# Espressif register map
File version: 1.0
CPU: Xtensa LX6 1, little endian, no MPU, FPU, 3 interrupt priority bits
Registers are 32-bit, access not given, reset 0x0 unless marked. A register's access mark holds for its fields unless they carry their own. Offsets are from the block's base; [hi:lo] are bit positions; {n}, {i} and the like mark numbered series.

## RTCCNTL
Base 0x3FF48000
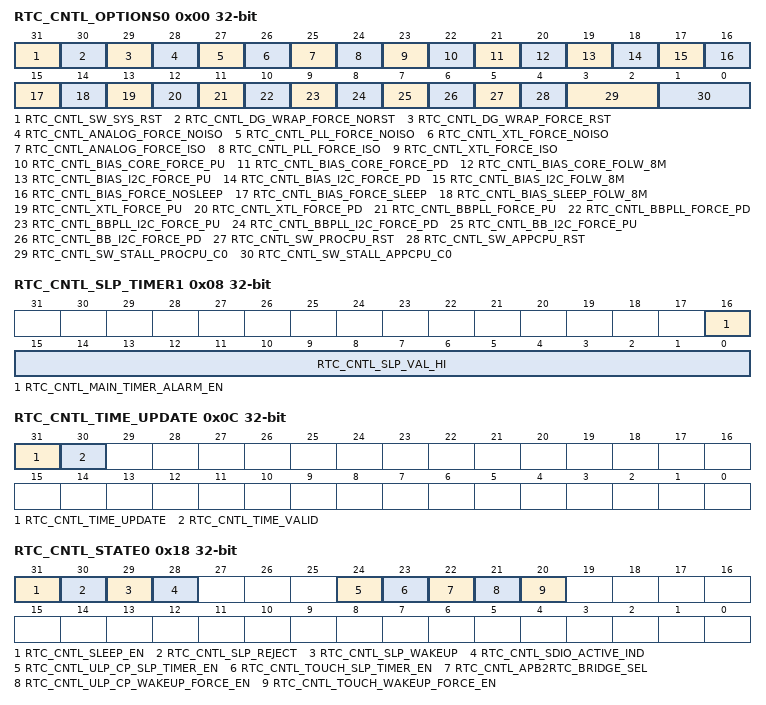
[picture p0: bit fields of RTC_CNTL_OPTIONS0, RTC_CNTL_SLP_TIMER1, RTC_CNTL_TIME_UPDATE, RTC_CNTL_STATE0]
0x00 RTC_CNTL_OPTIONS0
  [31] RTC_CNTL_SW_SYS_RST, [30] RTC_CNTL_DG_WRAP_FORCE_NORST, [29] RTC_CNTL_DG_WRAP_FORCE_RST, [28] RTC_CNTL_ANALOG_FORCE_NOISO, [27] RTC_CNTL_PLL_FORCE_NOISO, [26] RTC_CNTL_XTL_FORCE_NOISO, [25] RTC_CNTL_ANALOG_FORCE_ISO, [24] RTC_CNTL_PLL_FORCE_ISO, [23] RTC_CNTL_XTL_FORCE_ISO, [22] RTC_CNTL_BIAS_CORE_FORCE_PU, [21] RTC_CNTL_BIAS_CORE_FORCE_PD, [20] RTC_CNTL_BIAS_CORE_FOLW_8M, [19] RTC_CNTL_BIAS_I2C_FORCE_PU, [18] RTC_CNTL_BIAS_I2C_FORCE_PD, [17] RTC_CNTL_BIAS_I2C_FOLW_8M, [16] RTC_CNTL_BIAS_FORCE_NOSLEEP, [15] RTC_CNTL_BIAS_FORCE_SLEEP, [14] RTC_CNTL_BIAS_SLEEP_FOLW_8M, [13] RTC_CNTL_XTL_FORCE_PU, [12] RTC_CNTL_XTL_FORCE_PD, [11] RTC_CNTL_BBPLL_FORCE_PU, [10] RTC_CNTL_BBPLL_FORCE_PD, [9] RTC_CNTL_BBPLL_I2C_FORCE_PU, [8] RTC_CNTL_BBPLL_I2C_FORCE_PD, [7] RTC_CNTL_BB_I2C_FORCE_PU, [6] RTC_CNTL_BB_I2C_FORCE_PD, [5] RTC_CNTL_SW_PROCPU_RST, [4] RTC_CNTL_SW_APPCPU_RST, [3:2] RTC_CNTL_SW_STALL_PROCPU_C0, [1:0] RTC_CNTL_SW_STALL_APPCPU_C0
0x04 RTC_CNTL_SLP_TIMER0
  [31:0] RTC_CNTL_SLP_VAL_LO
0x08 RTC_CNTL_SLP_TIMER1
  [16] RTC_CNTL_MAIN_TIMER_ALARM_EN, [15:0] RTC_CNTL_SLP_VAL_HI
0x0C RTC_CNTL_TIME_UPDATE
  [31] RTC_CNTL_TIME_UPDATE, [30] RTC_CNTL_TIME_VALID
0x10 RTC_CNTL_TIME0
  [31:0] RTC_CNTL_TIME_LO
0x14 RTC_CNTL_TIME1
  [15:0] RTC_CNTL_TIME_HI
0x18 RTC_CNTL_STATE0
  [31] RTC_CNTL_SLEEP_EN, [30] RTC_CNTL_SLP_REJECT, [29] RTC_CNTL_SLP_WAKEUP, [28] RTC_CNTL_SDIO_ACTIVE_IND, [24] RTC_CNTL_ULP_CP_SLP_TIMER_EN, [23] RTC_CNTL_TOUCH_SLP_TIMER_EN, [22] RTC_CNTL_APB2RTC_BRIDGE_SEL, [21] RTC_CNTL_ULP_CP_WAKEUP_FORCE_EN, [20] RTC_CNTL_TOUCH_WAKEUP_FORCE_EN
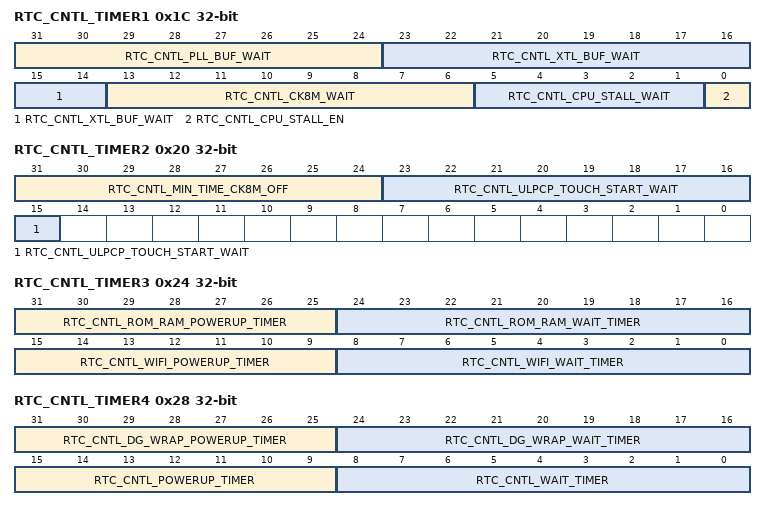
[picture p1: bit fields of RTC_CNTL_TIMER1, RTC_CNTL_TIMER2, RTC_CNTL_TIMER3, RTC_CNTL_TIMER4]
0x1C RTC_CNTL_TIMER1
  [31:24] RTC_CNTL_PLL_BUF_WAIT, [23:14] RTC_CNTL_XTL_BUF_WAIT, [13:6] RTC_CNTL_CK8M_WAIT, [5:1] RTC_CNTL_CPU_STALL_WAIT, [0] RTC_CNTL_CPU_STALL_EN
0x20 RTC_CNTL_TIMER2
  [31:24] RTC_CNTL_MIN_TIME_CK8M_OFF, [23:15] RTC_CNTL_ULPCP_TOUCH_START_WAIT
0x24 RTC_CNTL_TIMER3
  [31:25] RTC_CNTL_ROM_RAM_POWERUP_TIMER, [24:16] RTC_CNTL_ROM_RAM_WAIT_TIMER, [15:9] RTC_CNTL_WIFI_POWERUP_TIMER, [8:0] RTC_CNTL_WIFI_WAIT_TIMER
0x28 RTC_CNTL_TIMER4
  [31:25] RTC_CNTL_DG_WRAP_POWERUP_TIMER, [24:16] RTC_CNTL_DG_WRAP_WAIT_TIMER, [15:9] RTC_CNTL_POWERUP_TIMER, [8:0] RTC_CNTL_WAIT_TIMER
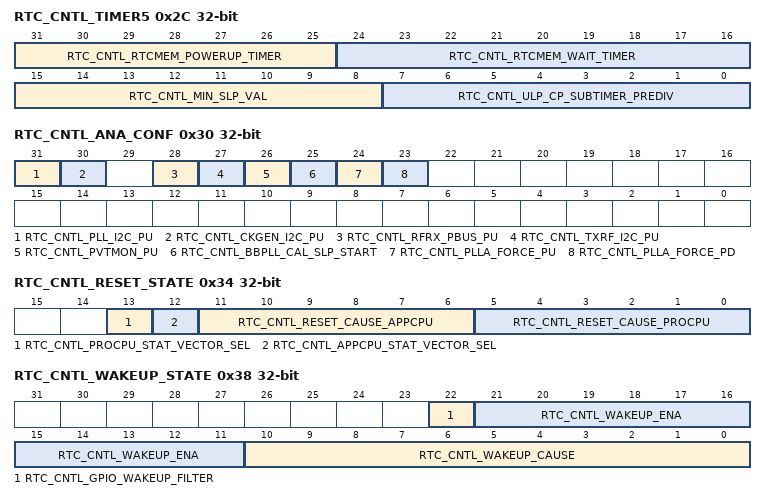
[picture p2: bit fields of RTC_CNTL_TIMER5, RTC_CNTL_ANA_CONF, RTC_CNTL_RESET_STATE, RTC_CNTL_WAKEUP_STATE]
0x2C RTC_CNTL_TIMER5
  [31:25] RTC_CNTL_RTCMEM_POWERUP_TIMER, [24:16] RTC_CNTL_RTCMEM_WAIT_TIMER, [15:8] RTC_CNTL_MIN_SLP_VAL, [7:0] RTC_CNTL_ULP_CP_SUBTIMER_PREDIV
0x30 RTC_CNTL_ANA_CONF
  [31] RTC_CNTL_PLL_I2C_PU, [30] RTC_CNTL_CKGEN_I2C_PU, [28] RTC_CNTL_RFRX_PBUS_PU, [27] RTC_CNTL_TXRF_I2C_PU, [26] RTC_CNTL_PVTMON_PU, [25] RTC_CNTL_BBPLL_CAL_SLP_START, [24] RTC_CNTL_PLLA_FORCE_PU, [23] RTC_CNTL_PLLA_FORCE_PD
0x34 RTC_CNTL_RESET_STATE
  [13] RTC_CNTL_PROCPU_STAT_VECTOR_SEL, [12] RTC_CNTL_APPCPU_STAT_VECTOR_SEL, [11:6] RTC_CNTL_RESET_CAUSE_APPCPU, [5:0] RTC_CNTL_RESET_CAUSE_PROCPU
0x38 RTC_CNTL_WAKEUP_STATE
  [22] RTC_CNTL_GPIO_WAKEUP_FILTER, [21:11] RTC_CNTL_WAKEUP_ENA, [10:0] RTC_CNTL_WAKEUP_CAUSE
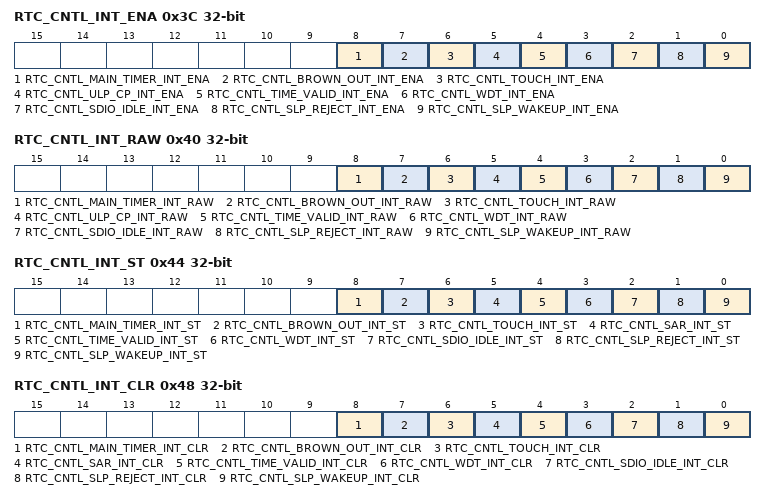
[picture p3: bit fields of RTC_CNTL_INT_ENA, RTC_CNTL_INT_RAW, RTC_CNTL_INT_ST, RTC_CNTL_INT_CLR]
0x3C RTC_CNTL_INT_ENA
  [8] RTC_CNTL_MAIN_TIMER_INT_ENA, [7] RTC_CNTL_BROWN_OUT_INT_ENA, [6] RTC_CNTL_TOUCH_INT_ENA, [5] RTC_CNTL_ULP_CP_INT_ENA, [4] RTC_CNTL_TIME_VALID_INT_ENA, [3] RTC_CNTL_WDT_INT_ENA, [2] RTC_CNTL_SDIO_IDLE_INT_ENA, [1] RTC_CNTL_SLP_REJECT_INT_ENA, [0] RTC_CNTL_SLP_WAKEUP_INT_ENA
0x40 RTC_CNTL_INT_RAW
  [8] RTC_CNTL_MAIN_TIMER_INT_RAW, [7] RTC_CNTL_BROWN_OUT_INT_RAW, [6] RTC_CNTL_TOUCH_INT_RAW, [5] RTC_CNTL_ULP_CP_INT_RAW, [4] RTC_CNTL_TIME_VALID_INT_RAW, [3] RTC_CNTL_WDT_INT_RAW, [2] RTC_CNTL_SDIO_IDLE_INT_RAW, [1] RTC_CNTL_SLP_REJECT_INT_RAW, [0] RTC_CNTL_SLP_WAKEUP_INT_RAW
0x44 RTC_CNTL_INT_ST
  [8] RTC_CNTL_MAIN_TIMER_INT_ST, [7] RTC_CNTL_BROWN_OUT_INT_ST, [6] RTC_CNTL_TOUCH_INT_ST, [5] RTC_CNTL_SAR_INT_ST, [4] RTC_CNTL_TIME_VALID_INT_ST, [3] RTC_CNTL_WDT_INT_ST, [2] RTC_CNTL_SDIO_IDLE_INT_ST, [1] RTC_CNTL_SLP_REJECT_INT_ST, [0] RTC_CNTL_SLP_WAKEUP_INT_ST
0x48 RTC_CNTL_INT_CLR
  [8] RTC_CNTL_MAIN_TIMER_INT_CLR, [7] RTC_CNTL_BROWN_OUT_INT_CLR, [6] RTC_CNTL_TOUCH_INT_CLR, [5] RTC_CNTL_SAR_INT_CLR, [4] RTC_CNTL_TIME_VALID_INT_CLR, [3] RTC_CNTL_WDT_INT_CLR, [2] RTC_CNTL_SDIO_IDLE_INT_CLR, [1] RTC_CNTL_SLP_REJECT_INT_CLR, [0] RTC_CNTL_SLP_WAKEUP_INT_CLR
{0x4C+4i} RTC_CNTL_STORE{i} (i=0..3)
  [31:0] RTC_CNTL_SCRATCH{i}
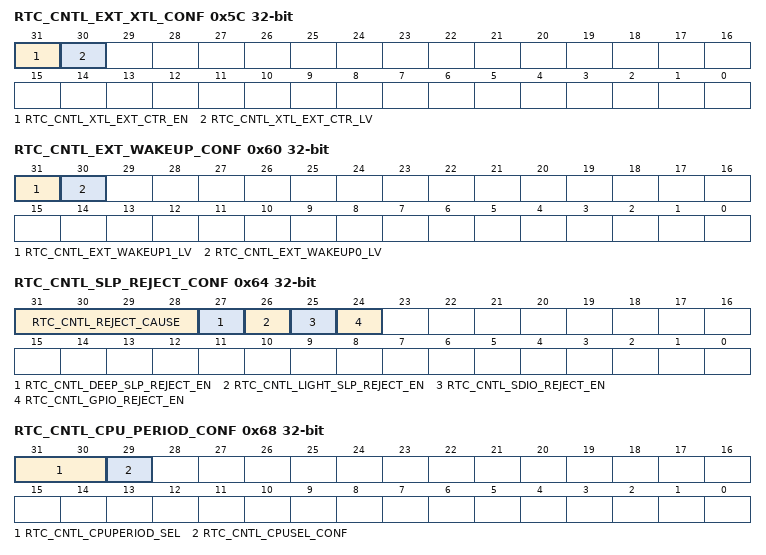
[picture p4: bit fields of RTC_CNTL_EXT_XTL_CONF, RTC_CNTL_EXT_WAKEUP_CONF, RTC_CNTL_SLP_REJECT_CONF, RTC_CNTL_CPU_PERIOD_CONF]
0x5C RTC_CNTL_EXT_XTL_CONF
  [31] RTC_CNTL_XTL_EXT_CTR_EN, [30] RTC_CNTL_XTL_EXT_CTR_LV
0x60 RTC_CNTL_EXT_WAKEUP_CONF
  [31] RTC_CNTL_EXT_WAKEUP1_LV, [30] RTC_CNTL_EXT_WAKEUP0_LV
0x64 RTC_CNTL_SLP_REJECT_CONF
  [31:28] RTC_CNTL_REJECT_CAUSE, [27] RTC_CNTL_DEEP_SLP_REJECT_EN, [26] RTC_CNTL_LIGHT_SLP_REJECT_EN, [25] RTC_CNTL_SDIO_REJECT_EN, [24] RTC_CNTL_GPIO_REJECT_EN
0x68 RTC_CNTL_CPU_PERIOD_CONF
  [31:30] RTC_CNTL_CPUPERIOD_SEL, [29] RTC_CNTL_CPUSEL_CONF
0x6C RTC_CNTL_SDIO_ACT_CONF
  [31:22] RTC_CNTL_SDIO_ACT_DNUM
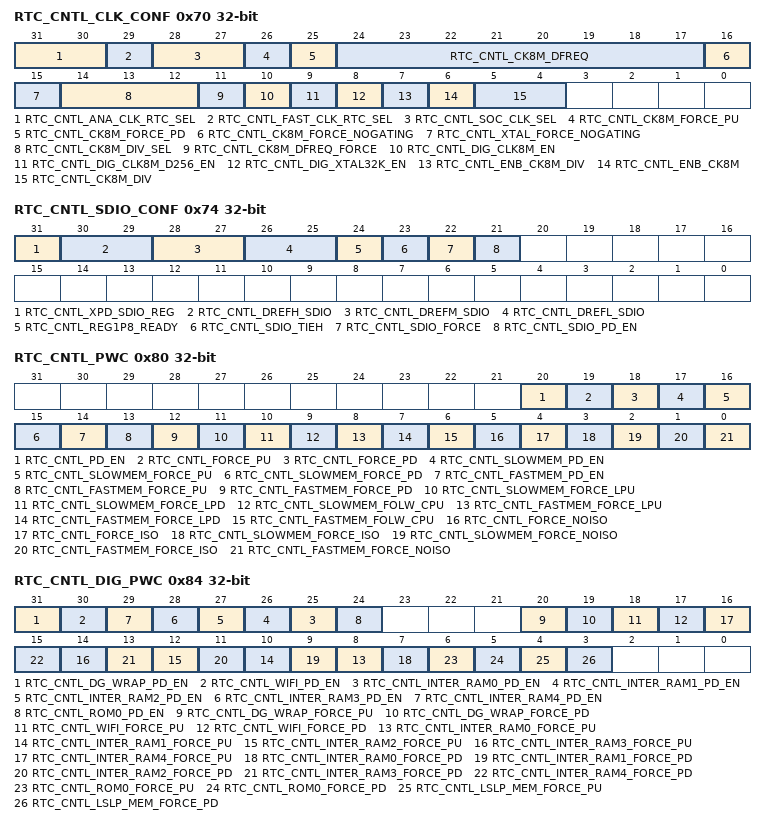
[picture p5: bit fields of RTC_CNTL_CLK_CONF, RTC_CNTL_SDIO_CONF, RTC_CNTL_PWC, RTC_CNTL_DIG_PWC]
0x70 RTC_CNTL_CLK_CONF
  [31:30] RTC_CNTL_ANA_CLK_RTC_SEL, [29] RTC_CNTL_FAST_CLK_RTC_SEL, [28:27] RTC_CNTL_SOC_CLK_SEL, [26] RTC_CNTL_CK8M_FORCE_PU, [25] RTC_CNTL_CK8M_FORCE_PD, [24:17] RTC_CNTL_CK8M_DFREQ, [16] RTC_CNTL_CK8M_FORCE_NOGATING, [15] RTC_CNTL_XTAL_FORCE_NOGATING, [14:12] RTC_CNTL_CK8M_DIV_SEL, [11] RTC_CNTL_CK8M_DFREQ_FORCE, [10] RTC_CNTL_DIG_CLK8M_EN, [9] RTC_CNTL_DIG_CLK8M_D256_EN, [8] RTC_CNTL_DIG_XTAL32K_EN, [7] RTC_CNTL_ENB_CK8M_DIV, [6] RTC_CNTL_ENB_CK8M, [5:4] RTC_CNTL_CK8M_DIV
0x74 RTC_CNTL_SDIO_CONF
  [31] RTC_CNTL_XPD_SDIO_REG, [30:29] RTC_CNTL_DREFH_SDIO, [28:27] RTC_CNTL_DREFM_SDIO, [26:25] RTC_CNTL_DREFL_SDIO, [24] RTC_CNTL_REG1P8_READY, [23] RTC_CNTL_SDIO_TIEH, [22] RTC_CNTL_SDIO_FORCE, [21] RTC_CNTL_SDIO_PD_EN
0x78 RTC_CNTL_BIAS_CONF
  [31] RTC_CNTL_RST_BIAS_I2C, [31] RTC_CNTL_FORCE_PU, [30] RTC_CNTL_DEC_HEARTBEAT_WIDTH, [30] RTC_CNTL_FORCE_PD, [29] RTC_CNTL_INC_HEARTBEAT_PERIOD, [29] RTC_CNTL_DBOOST_FORCE_PU, [28] RTC_CNTL_DEC_HEARTBEAT_PERIOD, [28] RTC_CNTL_DBOOST_FORCE_PD, [27] RTC_CNTL_INC_HEARTBEAT_REFRESH, [26] RTC_CNTL_ENB_SCK_XTAL, [27:25] RTC_CNTL_DBIAS_WAK, [25:24] RTC_CNTL_DBG_ATTEN, [24:22] RTC_CNTL_DBIAS_SLP, [21:14] RTC_CNTL_SCK_DCAP, [13:11] RTC_CNTL_DIG_DBIAS_WAK, [10:8] RTC_CNTL_DIG_DBIAS_SLP, [7] RTC_CNTL_SCK_DCAP_FORCE
0x80 RTC_CNTL_PWC
  [20] RTC_CNTL_PD_EN, [19] RTC_CNTL_FORCE_PU, [18] RTC_CNTL_FORCE_PD, [17] RTC_CNTL_SLOWMEM_PD_EN, [16] RTC_CNTL_SLOWMEM_FORCE_PU, [15] RTC_CNTL_SLOWMEM_FORCE_PD, [14] RTC_CNTL_FASTMEM_PD_EN, [13] RTC_CNTL_FASTMEM_FORCE_PU, [12] RTC_CNTL_FASTMEM_FORCE_PD, [11] RTC_CNTL_SLOWMEM_FORCE_LPU, [10] RTC_CNTL_SLOWMEM_FORCE_LPD, [9] RTC_CNTL_SLOWMEM_FOLW_CPU, [8] RTC_CNTL_FASTMEM_FORCE_LPU, [7] RTC_CNTL_FASTMEM_FORCE_LPD, [6] RTC_CNTL_FASTMEM_FOLW_CPU, [5] RTC_CNTL_FORCE_NOISO, [4] RTC_CNTL_FORCE_ISO, [3] RTC_CNTL_SLOWMEM_FORCE_ISO, [2] RTC_CNTL_SLOWMEM_FORCE_NOISO, [1] RTC_CNTL_FASTMEM_FORCE_ISO, [0] RTC_CNTL_FASTMEM_FORCE_NOISO
0x84 RTC_CNTL_DIG_PWC
  [31] RTC_CNTL_DG_WRAP_PD_EN, [30] RTC_CNTL_WIFI_PD_EN, [n+25] RTC_CNTL_INTER_RAM{n}_PD_EN (n=0..4), [24] RTC_CNTL_ROM0_PD_EN, [20] RTC_CNTL_DG_WRAP_FORCE_PU, [19] RTC_CNTL_DG_WRAP_FORCE_PD, [18] RTC_CNTL_WIFI_FORCE_PU, [17] RTC_CNTL_WIFI_FORCE_PD, [2n+8] RTC_CNTL_INTER_RAM{n}_FORCE_PU (n=0..4), [2n+7] RTC_CNTL_INTER_RAM{n}_FORCE_PD (n=0..4), [6] RTC_CNTL_ROM0_FORCE_PU, [5] RTC_CNTL_ROM0_FORCE_PD, [4] RTC_CNTL_LSLP_MEM_FORCE_PU, [3] RTC_CNTL_LSLP_MEM_FORCE_PD
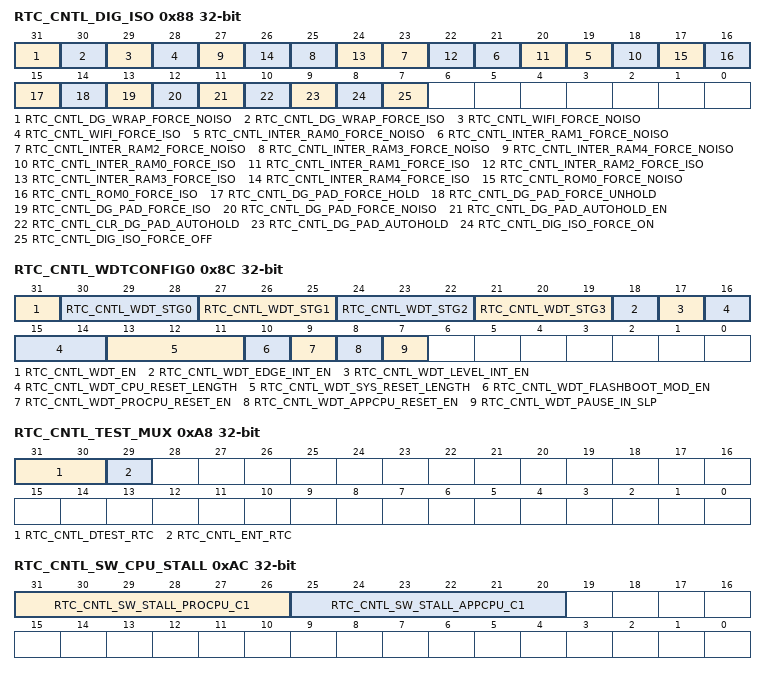
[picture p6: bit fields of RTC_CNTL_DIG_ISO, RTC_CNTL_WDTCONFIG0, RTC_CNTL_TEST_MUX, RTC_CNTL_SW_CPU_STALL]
0x88 RTC_CNTL_DIG_ISO
  [31] RTC_CNTL_DG_WRAP_FORCE_NOISO, [30] RTC_CNTL_DG_WRAP_FORCE_ISO, [29] RTC_CNTL_WIFI_FORCE_NOISO, [28] RTC_CNTL_WIFI_FORCE_ISO, [2n+19] RTC_CNTL_INTER_RAM{n}_FORCE_NOISO (n=0..4), [2n+18] RTC_CNTL_INTER_RAM{n}_FORCE_ISO (n=0..4), [17] RTC_CNTL_ROM0_FORCE_NOISO, [16] RTC_CNTL_ROM0_FORCE_ISO, [15] RTC_CNTL_DG_PAD_FORCE_HOLD, [14] RTC_CNTL_DG_PAD_FORCE_UNHOLD, [13] RTC_CNTL_DG_PAD_FORCE_ISO, [12] RTC_CNTL_DG_PAD_FORCE_NOISO, [11] RTC_CNTL_DG_PAD_AUTOHOLD_EN, [10] RTC_CNTL_CLR_DG_PAD_AUTOHOLD, [9] RTC_CNTL_DG_PAD_AUTOHOLD, [8] RTC_CNTL_DIG_ISO_FORCE_ON, [7] RTC_CNTL_DIG_ISO_FORCE_OFF
0x8C RTC_CNTL_WDTCONFIG0
  [31] RTC_CNTL_WDT_EN, [30-3n:28-3n] RTC_CNTL_WDT_STG{n} (n=0..3), [18] RTC_CNTL_WDT_EDGE_INT_EN, [17] RTC_CNTL_WDT_LEVEL_INT_EN, [16:14] RTC_CNTL_WDT_CPU_RESET_LENGTH, [13:11] RTC_CNTL_WDT_SYS_RESET_LENGTH, [10] RTC_CNTL_WDT_FLASHBOOT_MOD_EN, [9] RTC_CNTL_WDT_PROCPU_RESET_EN, [8] RTC_CNTL_WDT_APPCPU_RESET_EN, [7] RTC_CNTL_WDT_PAUSE_IN_SLP
{0x8C+4i} RTC_CNTL_WDTCONFIG{i} (i=1..4)
  [31:0] RTC_CNTL_WDT_STG{i-1}_HOLD
0xA0 RTC_CNTL_WDTFEED
  [31] RTC_CNTL_WDT_FEED
0xA4 RTC_CNTL_WDTWPROTECT
  [31:0] RTC_CNTL_WDT_WKEY
0xA8 RTC_CNTL_TEST_MUX
  [31:30] RTC_CNTL_DTEST_RTC, [29] RTC_CNTL_ENT_RTC
0xAC RTC_CNTL_SW_CPU_STALL
  [31:26] RTC_CNTL_SW_STALL_PROCPU_C1, [25:20] RTC_CNTL_SW_STALL_APPCPU_C1
{0xA0+4i} RTC_CNTL_STORE{i} (i=4..7)
  [31:0] RTC_CNTL_SCRATCH{i}
0xC4 RTC_CNTL_DIAG1
  [31:0] RTC_CNTL_LOW_POWER_DIAG1
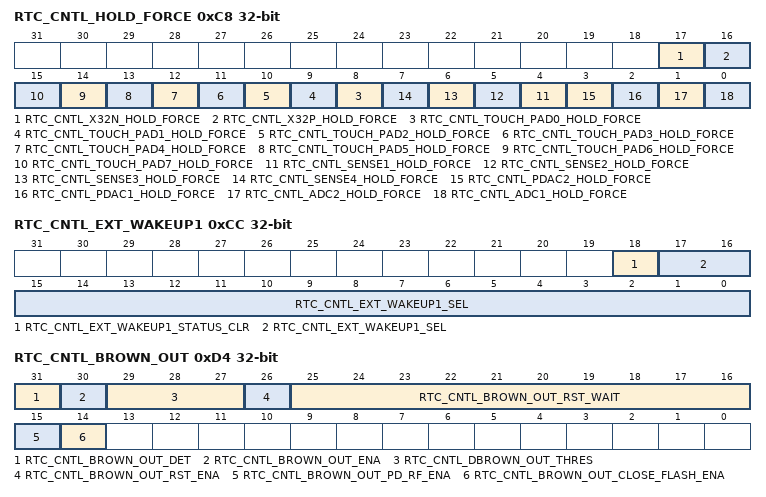
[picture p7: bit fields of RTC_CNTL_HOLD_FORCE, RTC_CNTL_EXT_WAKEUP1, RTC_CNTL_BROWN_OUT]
0xC8 RTC_CNTL_HOLD_FORCE
  [17] RTC_CNTL_X32N_HOLD_FORCE, [16] RTC_CNTL_X32P_HOLD_FORCE, [n+8] RTC_CNTL_TOUCH_PAD{n}_HOLD_FORCE (n=0..7), [n+3] RTC_CNTL_SENSE{n}_HOLD_FORCE (n=1..4), [3] RTC_CNTL_PDAC2_HOLD_FORCE, [2] RTC_CNTL_PDAC1_HOLD_FORCE, [1] RTC_CNTL_ADC2_HOLD_FORCE, [0] RTC_CNTL_ADC1_HOLD_FORCE
0xCC RTC_CNTL_EXT_WAKEUP1
  [18] RTC_CNTL_EXT_WAKEUP1_STATUS_CLR, [17:0] RTC_CNTL_EXT_WAKEUP1_SEL
0xD0 RTC_CNTL_EXT_WAKEUP1_STATUS
  [17:0] RTC_CNTL_EXT_WAKEUP1_STATUS
0xD4 RTC_CNTL_BROWN_OUT
  [31] RTC_CNTL_BROWN_OUT_DET, [30] RTC_CNTL_BROWN_OUT_ENA, [29:27] RTC_CNTL_DBROWN_OUT_THRES, [26] RTC_CNTL_BROWN_OUT_RST_ENA, [25:16] RTC_CNTL_BROWN_OUT_RST_WAIT, [15] RTC_CNTL_BROWN_OUT_PD_RF_ENA, [14] RTC_CNTL_BROWN_OUT_CLOSE_FLASH_ENA
0x13C RTC_CNTL_DATE
  [27:0] RTC_CNTL_CNTL_DATE
